# cslr_pciif register map
Vendor: Texas Instruments
Peripheral module from a debugger description file.
Registers are 32-bit, access per field, reset 0x0 unless marked. A register's access mark holds for its fields unless they carry their own. Offsets are as the file gives them; lines under a group give offsets from that group; [hi:lo] are bit positions; {n}, {i} and the like mark numbered series; 'fields as' and 'values as' point back to an identical list; <NAME> marks a mode.

## PCIIF — Peripheral Component Interconnect Interface
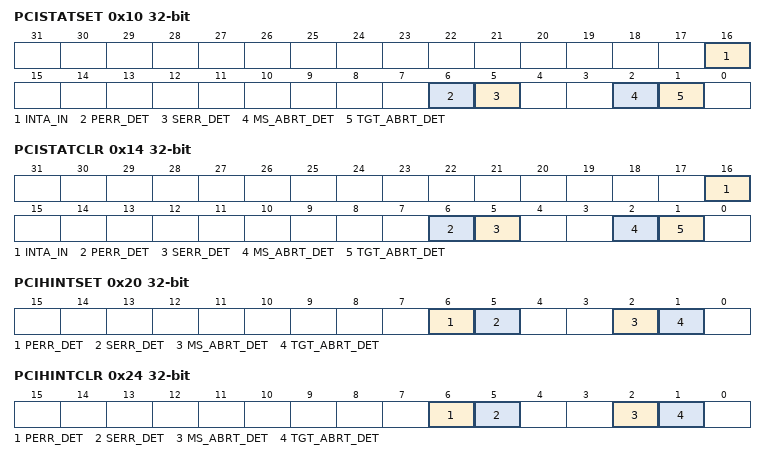
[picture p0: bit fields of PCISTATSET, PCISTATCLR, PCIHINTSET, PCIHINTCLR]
0x10 PCISTATSET access not given — Sets internal Status Register
  [16] INTA_IN — assert INTA_N input. 0 = INTA_N input de-asserted 1 = INTA_N input asserted (access RW1S)
  [6] PERR_DET — Set parity error. 0 = No parity error detected 1 = Parity error detected (access RW1S)
  [5] SERR_DET — Set system error. 0 = No system error detected 1 = System error detected (access RW1S)
  [2] MS_ABRT_DET — Set master abort bit 0 = No master abort detected. 1 = Master abort detected (access RW1S)
  [1] TGT_ABRT_DET — Set target abort bit 0 = No target abort detected 1 = Target abort detected (access RW1S)
0x14 PCISTATCLR access not given — Clears internal Status Register
  [16] INTA_IN — Clear INTA_N input 0 = INTA_N input de-asserted 1 = INTA_N input asserted (access RW1C)
  [6] PERR_DET — Clear Parity error detected 0 = No parity error detected 1 = Parity error detected (access RW1C)
  [5] SERR_DET — Clear System error detected 0 = No system error detected 1 = System error detected (access RW1C)
  [2] MS_ABRT_DET — Clear Master abort detected 0 = No master abort detected. 1 = Master abort detected (access RW1C)
  [1] TGT_ABRT_DET — Clear Target abort detected 0 = No target abort detected 1 = Target abort detected (access RW1C)
0x20 PCIHINTSET access not given — Set internal Host Interrupt Enable Register
  [6] PERR_DET — Interrupt enable for PERR_Det (access RW1S)
  [5] SERR_DET — Interrupt enable for SERR_Det (access RW1S)
  [2] MS_ABRT_DET — Interrupt enable for Master_Abort_Det (access RW1S)
  [1] TGT_ABRT_DET — Interrupt enable for Target_Abort_Det (access RW1S)
0x24 PCIHINTCLR access not given — Clear internal Host Interrupt Enable Register
  [6] PERR_DET — Clear Interrupt PERR_Det (access RW1C)
  [5] SERR_DET — Clear Interrupt SERR_Det (access RW1C)
  [2] MS_ABRT_DET — Clear Master abort detected (access RW1C)
  [1] TGT_ABRT_DET — Clear Target abort detected (access RW1C)
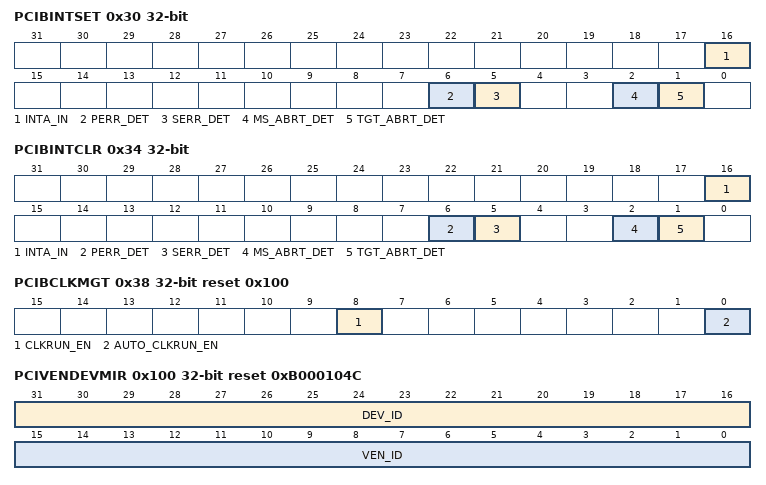
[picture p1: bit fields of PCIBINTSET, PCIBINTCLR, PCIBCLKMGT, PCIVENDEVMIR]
0x30 PCIBINTSET access not given — Set internal Back End Application Interrupt Enable Register
  [16] INTA_IN — Interrupt enable for INTA_In (access RW1S)
  [6] PERR_DET — Interrupt enable for PERR_Det (access RW1S)
  [5] SERR_DET — Interrupt enable for SERR_Det (access RW1S)
  [2] MS_ABRT_DET — Interrupt enable for Master_Abort_Det (access RW1S)
  [1] TGT_ABRT_DET — Interrupt enable for Target_Abort_Det (access RW1S)
0x34 PCIBINTCLR access not given — Clear internal Back End Application Interrupt Enable Register
  [16] INTA_IN — Clear Interrupt INTA_In (access RW1C)
  [6] PERR_DET — Clear Interrupt PERR_Det (access RW1C)
  [5] SERR_DET — Clear Interrupt SERR_Det (access RW1C)
  [2] MS_ABRT_DET — Clear Master abort detected (access RW1C)
  [1] TGT_ABRT_DET — Clear Target abort detected (access RW1C)
0x38 PCIBCLKMGT reset 0x100 — This register is used to control clock management behaviors that are specific to the back end application and its interaction with the PCIIF
  [8] CLKRUN_EN rw — This bit controls whether or not the PCIIF should always force the CLKRUN to stay asserted by reasserting CLKRUN whenever it is detected de-asserted
  [0] AUTO_CLKRUN_EN rw — This bit controls whether or not the PCIIF should automatically re-assert CLKRUN
0x100 PCIVENDEVMIR rw reset 0xB000104C — This register is used to initialize the Vendor ID and / or Device ID in the PCI Configuration Space
  [31:16] DEV_ID — Device ID. Identifies a specific device from the manufacturer. The Device ID is specified by the device manufacturer
  [15:0] VEN_ID — Vendor ID.Uniquely identifies the manufacturer of the device. The Vendor ID is specified by the PCI Special Interest Group to insure uniqueness
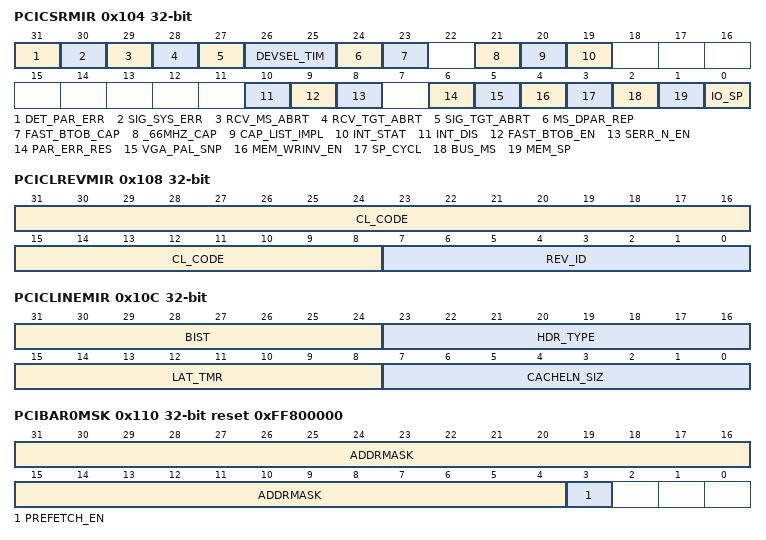
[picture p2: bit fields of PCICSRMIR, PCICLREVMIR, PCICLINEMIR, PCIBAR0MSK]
0x104 PCICSRMIR access not given (reset mask 0xF9DFFFFF) — This register is used to initialize certain bits in the PCI Configuration Space Command / Status register
  [31] DET_PAR_ERR — This bit is set by the PCIIF to indicate that it detected a parity error (access RW1C)
  [30] SIG_SYS_ERR — This bit is set by the PCIIF to indicate that it signaled a system error on the SERR_N pin. (access RW1C)
  [29] RCV_MS_ABRT — This bit is set by the PCI master unit in the PCIIF to indicate that it terminated a transaction with a master abort (access RW1C)
  [28] RCV_TGT_ABRT — This bit is set by the PCI master unit in the PCIIF to indicate that it has received a target abort when acting as a bus master (access RW1C)
  [27] SIG_TGT_ABRT ro — This bit is always 0 since the PCIIF cannot issue a target abort
  [26:25] DEVSEL_TIM ro — This bit indicates the decode response time capability of the device
  [24] MS_DPAR_REP — This bit is set by the PCI master unit in the PCIIF when all of the following conditions are met. 1.The PCIIF asserted PERR_N or observed PERR_N asserted 2.The PCIIF PCI master unit was the bus master during the observed PERR_N assertion 3. The Parity Error Response Bit is Set. (access RW1C)
  [23] FAST_BTOB_CAP ro — This bit indicates that the device is capable of performing fast back to back transactions
  [21] _66MHZ_CAP rw — This bit indicates whether or not the interface is capable of meeting the 66MHz PCI
  [20] CAP_LIST_IMPL rw — This bit indicates whether or not the interface provides at least one capabilities list
  [19] INT_STAT ro — This bit indicates the current interrupt status for the function as generated by the interrupt registers in the back end interface.
  [10] INT_DIS rw — This bit is a disable for the output driver on the INTA_N pin
  [9] FAST_BTOB_EN ro — This bit controls whether or not the device is allowed to perform back to back writes to different targets.
  [8] SERR_N_EN rw — This bit is an enable for the output driver on the SERR_N pin
  [6] PAR_ERR_RES rw — This bit controls whether or not the device responds to detected parity errors.
  [5] VGA_PAL_SNP ro — VGA Palette Snoop
  [4] MEM_WRINV_EN rw — This bit enables the device to use the Memory Write and Invalidate command.
  [3] SP_CYCL ro — This bit controls the device's response to special cycle commands
  [2] BUS_MS rw — This bit enables the device to act as a PCI bus master
  [1] MEM_SP rw — This bit enables the device to respond to memory accesses within it's address space
  [0] IO_SP ro — This bit enables the device to respond to I/O accesses within it's address space. If this bit is cleared, the PCIIF will not respond to IO mapped accesses
0x108 PCICLREVMIR rw reset not defined — This register is used to initialize the Class Code and / or Revision ID
  [31:8] CL_CODE — Class Code. Identifies the generic and specific function and programming interface of the device. The Class Code is specified by the device manufacturer
  [7:0] REV_ID — Revision ID. Identifies a revision of the specific device. The Revision ID is specified by the device manufacturer
0x10C PCICLINEMIR — This register is used to set latency timer and cacheline size
  [31:24] BIST ro — Hardwired to 0
  [23:16] HDR_TYPE ro — Header Type. Identifies the layout of bytes 10h through 3Fh and if the device is single or multi-function
  [15:8] LAT_TMR rw — Latency Timer. The latency timer register is provided so that the host can restrict the continued usage of the PCI bus by a master involved in a multiple data cycle transaction.
  [7:0] CACHELN_SIZ rw — Cacheline Size.This register is provided so that the host can inform the device of the cache line size in units of 32 bit words.
0x110 PCIBAR0MSK reset 0xFF800000 (reset mask 0xFFFFFFF7) — The Base Address Mask Registers control the size and prefetchability of the PCI Configuration Base Address Registers
  [31:4] ADDRMASK rw — Address Mask Bit.These bits control the writability of corresponding bits in the corresponding PCI Configuration Base Address Register.
  [3] PREFETCH_EN rw — Prefetchable enable. This bit specifies whether or not the memory space controlled by the corresponding PCI Configruation Base Address Register is prefetchable.
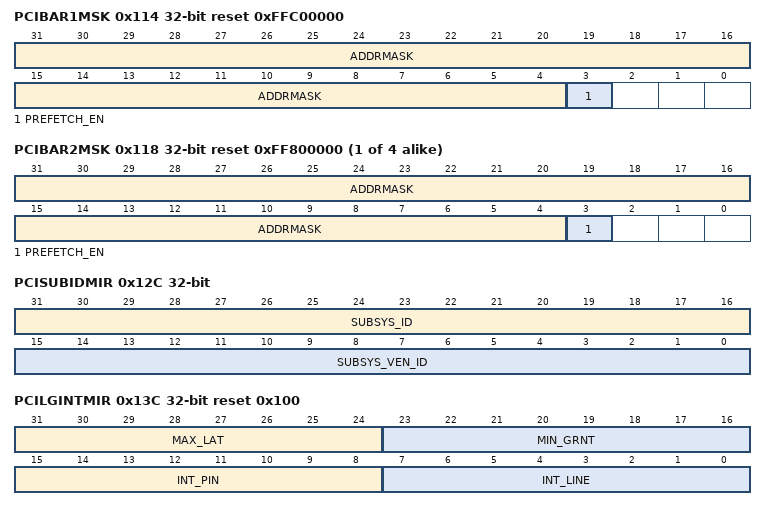
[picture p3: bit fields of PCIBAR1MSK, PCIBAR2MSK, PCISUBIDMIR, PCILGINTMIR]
0x114 PCIBAR1MSK reset 0xFFC00000 (reset mask 0xFFFFFFF7) — The Base Address Mask Registers control the size and prefetchability of the PCI Configuration Base Address Registers
  fields as PCIBAR0MSK
{0x110+4i} PCIBAR{i}MSK reset 0xFF800000 (reset mask 0xFFFFFFF7) (i=2..5) — The Base Address Mask Registers control the size and prefetchability of the PCI Configuration Base Address Registers
  fields as PCIBAR0MSK
0x12C PCISUBIDMIR rw — PCIIF Subsystem Vendor ID / Subsystem ID
  [31:16] SUBSYS_ID — Subsystem Id. Identifies the board level device.The Subsystem ID is specified by the board level manufacturer.
  [15:0] SUBSYS_VEN_ID — Subsystem Vendor Id. Identifies the board level manufacturer. The Subsystem Vendor ID is specified by the PCI Special Interest Group.
0x134 PCICPBPTRMIR ro reset 0x40 — Capabilities Pointer
  [7:0] CAP — Capabilities Pointer. This constant specifies the address in configuration space where the first entry in the capabilities list is located.
0x13C PCILGINTMIR reset 0x100 — Set Max Latency / Min Grant
  [31:24] MAX_LAT rw — This specifies how often the device needs to gain access to the PCI bus in 0.25 micro sec units.
  [23:16] MIN_GRNT rw — This specifies the length of the burst period for the device needs in 0.25 micro sec units.
  [15:8] INT_PIN ro — This register tells which interrupt pin the device uses. This register is hardwired to a 01h in the PCIIF to indicate that interrupt A will be used.
  [7:0] INT_LINE rw — The value in this 8 bit register is written by the host and indicates which input of the system interrupt controller the PCIIF interrupt pin is connected to.
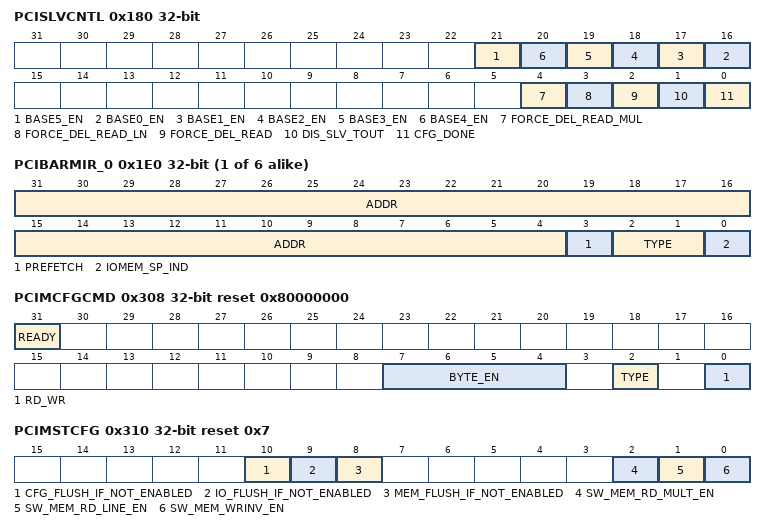
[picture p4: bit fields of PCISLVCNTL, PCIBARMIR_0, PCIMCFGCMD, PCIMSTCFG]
0x180 PCISLVCNTL (reset mask 0xFFC0FFFF) — PCIIF Slave Control
  [21] BASE5_EN rw — Enable BASE 5 Config. 0 = Disable BASE 5 Config 1 = Enable BASE 5 Config
  [n+16] BASE{n}_EN rw (n=0..4) — Enable BASE {n} Config 0 = Disable BASE {n} Config 1 = Enable BASE {n} Config
  [4] FORCE_DEL_READ_MUL rw — Force Delayed Read Multiple. 0 = Slave should respond with normal 16 clock cycle timeout and retry mechanism for Memory Read Multiple transactions 1 = Slave should immediately respond with a retry whenever a Memory Read Multiple transaction is decoded for this slave.
  [3] FORCE_DEL_READ_LN rw — Force Delayed Read Line. 0 = Slave should respond with normal 16 clock cycle timeout and retry mechanism for Memory Read Line transactions 1 = Slave should immediately respond with a retry whenever a Memory Read Line transaction is decoded for this slave.
  [2] FORCE_DEL_READ rw — Force Delayed Read. 0 = Slave should respond with normal 16 clock cycle timeout and retry mechanism for Memory Read transactions 1 = Slave should immediately respond with a retry whenever a Memory Read transaction is decoded for this slave.
  [1] DIS_SLV_TOUT rw — Disable Slave timeout. 0 = Slave responds with normal 16 clock cycle timeout mechanism 1 = Slave will insert wait states on the PCI Bus indefinitely until the access is ready to complete
  [0] CFG_DONE rw — Indicates if the Configuration Registers have been loaded with their proper reset values: 0 = Configuration Registers are being loaded. No access allowed into PCI interface. 1 = Configuration Registers loading is complete. PCI interface will accept accesses.
0x1C0 PCIBAR0TRL reset 0x800000 — This register control the translation of transaction addresses
  [31:4] TRANS_ADDR rw — This is the address that is to bitwise replace the slave transaction address.This is multiplexed on a bitwise basis with the original PCI address using the corresponding PCIIF Base Address Mask register bits 31:4 as the multiplexer select.
0x1C4 PCIBAR1TRL reset 0x1800000 — This register control the translation of transaction addresses
  fields as PCIBAR0TRL
0x1C8 PCIBAR2TRL reset 0x2800000 — This register control the translation of transaction addresses
  fields as PCIBAR0TRL
0x1CC PCIBAR3TRL reset 0x80000000 — This register control the translation of transaction addresses
  fields as PCIBAR0TRL
0x1D0 PCIBAR4TRL reset 0xA0000000 — This register control the translation of transaction addresses
  fields as PCIBAR0TRL
0x1D4 PCIBAR5TRL reset 0xE0000000 — This register control the translation of transaction addresses
  fields as PCIBAR0TRL
{0x1E0+4i} PCIBARMIR_{i} (reset mask 0xFFFFFFF7) (i=0..5) — PCIIF Base Address Mirror Register
  [31:4] ADDR rw — These bits can be written by the host in order to allow initialization of the base address at startup
  [3] PREFETCH ro — This bit specifies whether or not the memory space controlled by this base address register is prefetchable
  [2:1] TYPE ro — These bits indicate the size of the base address register
  [0] IOMEM_SP_IND ro — This bit indicates whether the base address maps into the host's memory or I/O space
0x300 PCIMCFGDAT rw — PCIIF Master Configuration / IO Access Data Register
  [31:0] DATA — Software writes the data into this register bit for a configuration/IO write, or reads the data from this register for a configuration/IO read.
0x304 PCIMCFGADR rw — PCIIF Master Configuration / IO Access Address Register
  [31:0] ADDR — Address for Configuration/IO Transaction. Bits 1:0 are ignored for a Configuration Transaction. Software must ensure that Bits 1:0 of the Address correspond to the Byte_Enables that are written in the Configuration / IO Access Command register for IO transactions to ensure that the access is legal on the PCI bus.
0x308 PCIMCFGCMD reset 0x80000000 — PCIIF Master Configuration / IO Access Command Register
  [31] READY ro — The ready bit should be checked to assure previous transaction is complete
  [7:4] BYTE_EN rw — Byte Enables
  [2] TYPE rw — Set Configuration and IO Transaction 0 = Configuration Transaction 1 = IO Transaction
    0=CONFIG_SPACE (Enable Configuration space access); 1=IO_SPACE (Enable IO space access)
  [0] RD_WR rw — Set read and write operation 0 = Write 1 = Read
    0=WRITE (Enable Configration/IO Write); 1=READ (Enable Configration/IO Read)
0x310 PCIMSTCFG reset 0x7 — PCIIF Master Configuration Register
  [10] CFG_FLUSH_IF_NOT_ENABLED rw — Controls whether or not the Master will flush Configuration transactions from the proxyregisters if the Master is not enabled
  [9] IO_FLUSH_IF_NOT_ENABLED rw — Controls whether or not the Master will flush I/O transactions from the proxy registers if the Master is not enabled
  [8] MEM_FLUSH_IF_NOT_ENABLED rw — Controls whether or not the Master will flush transactions on the pcim interface if the Master is not enabled
  [2] SW_MEM_RD_MULT_EN rw — Controls whether or not the Master command generation logic is permitted to use the Memory Read Multiple command
  [1] SW_MEM_RD_LINE_EN rw — Controls whether or not the Master command generation logic is permitted to use the Memory Read Line command
  [0] SW_MEM_WRINV_EN rw — Controls whether or not the Master command generation logic is permitted to use the Memory Write and Invalidate command
{0x314+4i} PCIADDSUB_{i} (i=0..31) — Address Translation Register
  [31:23] ADD_SUBS rw — Substitutes the 9 MSBs of VBUS address
0x394 PCIVENDEVPRG rw reset 0xB000104C — Provides default values for the vendor and device id
  [31:0] VALUE — Default value of vendor_id, device_id
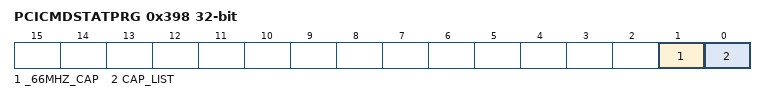
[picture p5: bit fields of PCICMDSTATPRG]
0x398 PCICMDSTATPRG (reset mask 0xFFFFFFFD) — Provides default values for the command status mirror register
  [1] _66MHZ_CAP rw — Default value for 66MHz capable field of command status register of PCIIF
  [0] CAP_LIST rw — Default value for capabilities list implemented field of command status register of PCIIF
0x39C PCICLREVPRG rw reset 0x1 — Provides default values to Class code/Revision ID mirror register
  [31:0] VALUE — Default value for class code and revision id
0x3A0 PCISUBIDPRG rw — Provides default values to subsystem vendor id and subsystem id
  [31:0] VALUE — Default value for subsystem vendor id and subsystem id
0x3A4 PCIMAXLGPRG — Provides default values for max latency and min grant
  [15:0] VALUE rw — Default values for max latency and min grant
0x3A8 PCILRSTREG (reset mask 0xFFFFFFFE) — Supplies lreset to GEM
  [0] LRESET rw — Provides lreset to GEM via boot_controller
0x3AC PCICFGDONE (reset mask 0xFFFFFFFE) — Supplies config done to pciif core
  [0] CONFIG_DONE rw — Provides config done to pciif_core. Reset by hard reset from pll and reset controller
0x3B0 PCIBAR0MPRG reset 0xFFC0000 — Default value for PCI base address mask register0
  [27:0] MASK rw — Provides default value for Base address mask register0
0x3B4 PCIBAR1MPRG reset 0xFF80000 — Default value for PCI base address mask register1
  [27:0] MASK rw — Provides default value for Base address mask register1
0x3B8 PCIBAR2MPRG reset 0xFFFFFFF — Default value for PCI base address mask register2
  [27:0] MASK rw — Provides default value for Base address mask register2
{0x3B0+4i} PCIBAR{i}MPRG (i=3..5) — Default value for PCI base address mask register{i}
  [27:0] MASK rw — Provides default value for Base address mask register{i}
0x3C8 PCIBAR0PRG reset 0x1 — Default value for PCI base address register0
  [0] VAL rw — Provides default value for prefetchable bit of Base address register0
{0x3C8+4i} PCIBAR{i}PRG (i=1..5) — Default value for PCI base address register{i}
  [0] VAL rw — Provides default value for prefetchable bit of Base address register{i}
0x3E0 PCIBAR0TRLPRG reset 0x80000 — Default value for Base address translation register0
  [27:0] TRANS_ADDR rw — Provides default value for Base address translation register0
0x3E4 PCIBAR1TRLPRG reset 0x180000 — Default value for Base address translation register1
  [27:0] TRANS_ADDR rw — Provides default value for Base address translation register1
0x3E8 PCIBAR2TRLPRG reset 0x280000 — Default value for Base address translation register2
  [27:0] TRANS_ADDR rw — Provides default value for Base address translation register2
0x3EC PCIBAR3TRLPRG reset 0x8000000 — Default value for Base address translation register3
  [27:0] TRANS_ADDR rw — Provides default value for Base address translation register3
0x3F0 PCIBAR4TRLPRG reset 0xA000000 — Default value for Base address translation register4
  [27:0] TRANS_ADDR rw — Provides default value for Base address translation register4
0x3F4 PCIBAR5TRLPRG reset 0xE000000 — Default value for Base address translation register5
  [27:0] TRANS_ADDR rw — Provides default value for Base address translation register5
0x3F8 PCIBASENPRG reset 0x3F — Default value for enables for the base address
  [5:0] BASE_EN rw — Provides default value for base address enable for base address0 (bit 0), base address1 (bit1), base address2 (bit2), base address3 (bit3), base address4 (bit4),base address5 (bit5)
